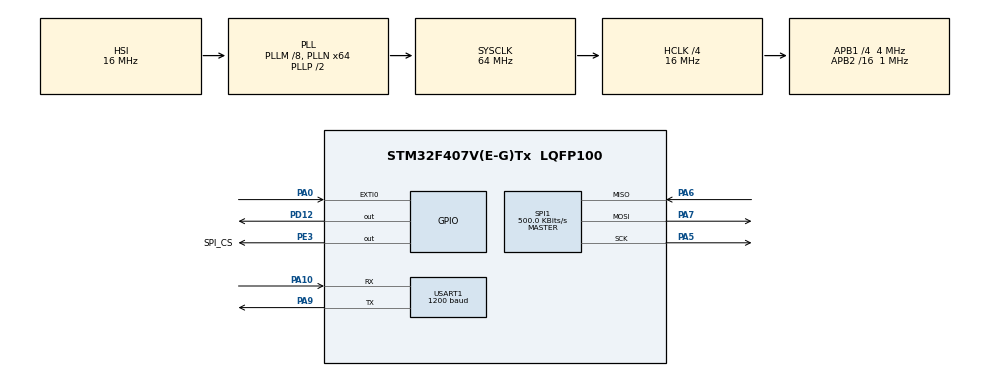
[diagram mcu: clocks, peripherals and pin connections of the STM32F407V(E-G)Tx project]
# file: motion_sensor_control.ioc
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Mcu.Family=STM32F4
Mcu.Name=STM32F407V(E-G)Tx
Mcu.Package=LQFP100
NVIC.EXTI0_IRQn=true\:0\:0\:false\:false\:true\:true\:true\:true
NVIC.PriorityGroup=NVIC_PRIORITYGROUP_4
NVIC.SPI1_IRQn=true\:0\:0\:false\:false\:true\:true\:true\:true
NVIC.USART1_IRQn=true\:0\:0\:false\:false\:true\:true\:true\:true
PA0-WKUP.Signal=GPXTI0
PA10.Mode=Asynchronous
PA10.Signal=USART1_RX
PA5.Mode=Full_Duplex_Master
PA5.Signal=SPI1_SCK
PA6.Mode=Full_Duplex_Master
PA6.Signal=SPI1_MISO
PA7.Mode=Full_Duplex_Master
PA7.Signal=SPI1_MOSI
PA9.Mode=Asynchronous
PA9.Signal=USART1_TX
PD12.Signal=GPIO_Output
PE3.GPIO_Label=SPI_CS
PE3.Signal=GPIO_Output
PH0-OSC_IN.Mode=HSE-External-Oscillator
PH0-OSC_IN.Signal=RCC_OSC_IN
PH1-OSC_OUT.Mode=HSE-External-Oscillator
PH1-OSC_OUT.Signal=RCC_OSC_OUT
ProjectManager.HeapSize=0x200
ProjectManager.StackSize=0x400
ProjectManager.TargetToolchain=STM32CubeIDE
RCC.48MHZClocksFreq_Value=32000000
RCC.AHBCLKDivider=RCC_SYSCLK_DIV4
RCC.AHBFreq_Value=16000000
RCC.APB1CLKDivider=RCC_HCLK_DIV4
RCC.APB1Freq_Value=4000000
RCC.APB1TimFreq_Value=8000000
RCC.APB2CLKDivider=RCC_HCLK_DIV16
RCC.APB2Freq_Value=1000000
RCC.APB2TimFreq_Value=2000000
RCC.CortexFreq_Value=16000000
RCC.HCLKFreq_Value=16000000
RCC.HSE_VALUE=25000000
RCC.HSI_VALUE=16000000
RCC.LSE_VALUE=32768
RCC.PLLM=8
RCC.PLLN=64
RCC.SYSCLKFreq_VALUE=64000000
RCC.SYSCLKSource=RCC_SYSCLKSOURCE_PLLCLK
RCC.VCOOutputFreq_Value=128000000
SPI1.CalculateBaudRate=500.0 KBits/s
SPI1.Direction=SPI_DIRECTION_2LINES
SPI1.Mode=SPI_MODE_MASTER
SPI1.VirtualType=VM_MASTER
USART1.BaudRate=1200
USART1.VirtualMode=VM_ASYNC
board=custom

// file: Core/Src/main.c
#include "main.h"
#include "my_lis302dl.h"

SPI_HandleTypeDef hspi1;

UART_HandleTypeDef huart1;

Lis302dl_InitTypeDef LIS302DL_InitStruct;

void SystemClock_Config(void);
static void MX_GPIO_Init(void);
static void MX_SPI1_Init(void);
static void MX_USART1_UART_Init(void);

static void MX_LIS302DL_Init(void);

LIS302DL_DataRaw data;

int8_t x,y,z;
uint8_t veri[6];
uint8_t pydata[1];

  /* NOTE: This function Should not be modified, when the callback is needed,
           the HAL_GPIO_EXTI_Callback could be implemented in the user file
   */
void HAL_UART_RxCpltCallback(UART_HandleTypeDef *huart)
{
  HAL_UART_Receive_IT(&huart1, (uint8_t*)pydata, 1);
}

/* USER CODE END PFP */

int main(void)
{

  /* MCU Configuration--------------------------------------------------------*/

  /* Reset of all peripherals, Initializes the Flash interface and the Systick. */
  HAL_Init();

  /* Configure the system clock */
  SystemClock_Config();

  /* Initialize all configured peripherals */
  MX_GPIO_Init();
  MX_SPI1_Init();
  MX_USART1_UART_Init();
  MX_LIS302DL_Init();

  HAL_UART_Receive_IT(&huart1, (uint8_t*)pydata, 1);

  /* USER CODE BEGIN WHILE */
  while (1)
  {
	    data = LIS302DL_GetDataRaw();
	    x = LIS302DL_X_calibrate();
	    y = LIS302DL_Y_calibrate();

	    if( pydata[0]== 'A'){

	    	veri[0] =0x65;
	    	veri[1] = 0x65;
	    	veri[2] = x;
	    	veri[3] = y;
	    	veri[4] = 0x90;
	    	veri[5] = 0x90;

	    	HAL_UART_Transmit(&huart1,(uint8_t*)veri ,6, 100);

	    }

  }

}

void SystemClock_Config(void)
{
  RCC_OscInitTypeDef RCC_OscInitStruct = {0};
  RCC_ClkInitTypeDef RCC_ClkInitStruct = {0};

  /** Configure the main internal regulator output voltage
  */
  __HAL_RCC_PWR_CLK_ENABLE();
  __HAL_PWR_VOLTAGESCALING_CONFIG(PWR_REGULATOR_VOLTAGE_SCALE1);

  /** Initializes the RCC Oscillators according to the specified parameters
  * in the RCC_OscInitTypeDef structure.
  */
  RCC_OscInitStruct.OscillatorType = RCC_OSCILLATORTYPE_HSI;
  RCC_OscInitStruct.HSIState = RCC_HSI_ON;
  RCC_OscInitStruct.HSICalibrationValue = RCC_HSICALIBRATION_DEFAULT;
  RCC_OscInitStruct.PLL.PLLState = RCC_PLL_ON;
  RCC_OscInitStruct.PLL.PLLSource = RCC_PLLSOURCE_HSI;
  RCC_OscInitStruct.PLL.PLLM = 8;
  RCC_OscInitStruct.PLL.PLLN = 64;
  RCC_OscInitStruct.PLL.PLLP = RCC_PLLP_DIV2;
  RCC_OscInitStruct.PLL.PLLQ = 4;
  if (HAL_RCC_OscConfig(&RCC_OscInitStruct) != HAL_OK)
  {
    Error_Handler();
  }

  /** Initializes the CPU, AHB and APB buses clocks
  */
  RCC_ClkInitStruct.ClockType = RCC_CLOCKTYPE_HCLK|RCC_CLOCKTYPE_SYSCLK
                              |RCC_CLOCKTYPE_PCLK1|RCC_CLOCKTYPE_PCLK2;
  RCC_ClkInitStruct.SYSCLKSource = RCC_SYSCLKSOURCE_PLLCLK;
  RCC_ClkInitStruct.AHBCLKDivider = RCC_SYSCLK_DIV4;
  RCC_ClkInitStruct.APB1CLKDivider = RCC_HCLK_DIV4;
  RCC_ClkInitStruct.APB2CLKDivider = RCC_HCLK_DIV16;

  if (HAL_RCC_ClockConfig(&RCC_ClkInitStruct, FLASH_LATENCY_0) != HAL_OK)
  {
    Error_Handler();
  }
}

static void MX_SPI1_Init(void)
{

  /* SPI1 parameter configuration*/
  hspi1.Instance = SPI1;
  hspi1.Init.Mode = SPI_MODE_MASTER;
  hspi1.Init.Direction = SPI_DIRECTION_2LINES;
  hspi1.Init.DataSize = SPI_DATASIZE_8BIT;
  hspi1.Init.CLKPolarity = SPI_POLARITY_LOW;
  hspi1.Init.CLKPhase = SPI_PHASE_1EDGE;
  hspi1.Init.NSS = SPI_NSS_SOFT;
  hspi1.Init.BaudRatePrescaler = SPI_BAUDRATEPRESCALER_2;
  hspi1.Init.FirstBit = SPI_FIRSTBIT_MSB;
  hspi1.Init.TIMode = SPI_TIMODE_DISABLE;
  hspi1.Init.CRCCalculation = SPI_CRCCALCULATION_DISABLE;
  hspi1.Init.CRCPolynomial = 10;
  if (HAL_SPI_Init(&hspi1) != HAL_OK)
  {
    Error_Handler();
  }

}

static void MX_USART1_UART_Init(void)
{

  huart1.Instance = USART1;
  huart1.Init.BaudRate = 1200;
  huart1.Init.WordLength = UART_WORDLENGTH_8B;
  huart1.Init.StopBits = UART_STOPBITS_1;
  huart1.Init.Parity = UART_PARITY_NONE;
  huart1.Init.Mode = UART_MODE_TX_RX;
  huart1.Init.HwFlowCtl = UART_HWCONTROL_NONE;
  huart1.Init.OverSampling = UART_OVERSAMPLING_16;
  if (HAL_UART_Init(&huart1) != HAL_OK)
  {
    Error_Handler();
  }

}

static void MX_GPIO_Init(void)
{
  GPIO_InitTypeDef GPIO_InitStruct = {0};

  /* GPIO Ports Clock Enable */
  __HAL_RCC_GPIOE_CLK_ENABLE();
  __HAL_RCC_GPIOH_CLK_ENABLE();
  __HAL_RCC_GPIOA_CLK_ENABLE();
  __HAL_RCC_GPIOD_CLK_ENABLE();

  /*Configure GPIO pin Output Level */
  HAL_GPIO_WritePin(SPI_CS_GPIO_Port, SPI_CS_Pin, GPIO_PIN_RESET);

  /*Configure GPIO pin Output Level */
  HAL_GPIO_WritePin(GPIOD, GPIO_PIN_12, GPIO_PIN_RESET);

  /*Configure GPIO pin : SPI_CS_Pin */
  GPIO_InitStruct.Pin = SPI_CS_Pin;
  GPIO_InitStruct.Mode = GPIO_MODE_OUTPUT_PP;
  GPIO_InitStruct.Pull = GPIO_NOPULL;
  GPIO_InitStruct.Speed = GPIO_SPEED_FREQ_LOW;
  HAL_GPIO_Init(SPI_CS_GPIO_Port, &GPIO_InitStruct);

  /*Configure GPIO pin : PA0 */
  GPIO_InitStruct.Pin = GPIO_PIN_0;
  GPIO_InitStruct.Mode = GPIO_MODE_IT_RISING;
  GPIO_InitStruct.Pull = GPIO_NOPULL;
  HAL_GPIO_Init(GPIOA, &GPIO_InitStruct);

  /*Configure GPIO pin : PD12 */
  GPIO_InitStruct.Pin = GPIO_PIN_12;
  GPIO_InitStruct.Mode = GPIO_MODE_OUTPUT_PP;
  GPIO_InitStruct.Pull = GPIO_NOPULL;
  GPIO_InitStruct.Speed = GPIO_SPEED_FREQ_LOW;
  HAL_GPIO_Init(GPIOD, &GPIO_InitStruct);

  /* EXTI interrupt init*/
  HAL_NVIC_SetPriority(EXTI0_IRQn, 0, 0);
  HAL_NVIC_EnableIRQ(EXTI0_IRQn);

}

/* USER CODE BEGIN 4 */
static void MX_LIS302DL_Init(void){
	LIS302DL_InitStruct.Axis_Mode =XYZ_ENABLE;
	LIS302DL_InitStruct.Full_Scale_Mode =FUL_SCALE_2G;
	LIS302DL_InitStruct.Data_Rate = DATA_RATE_100HZ;
	LIS302DL_InitStruct.Power_Mode = POWER_ACTIVE_MODE;
	LIS302DL_InitStruct.Self_Test_Mode = SELF_TEST_NORMAL;
	Lis302dl_Init(&LIS302DL_InitStruct);

}
/* USER CODE END 4 */

void Error_Handler(void)
{
  __disable_irq();
  while (1)
  {
  }
}
